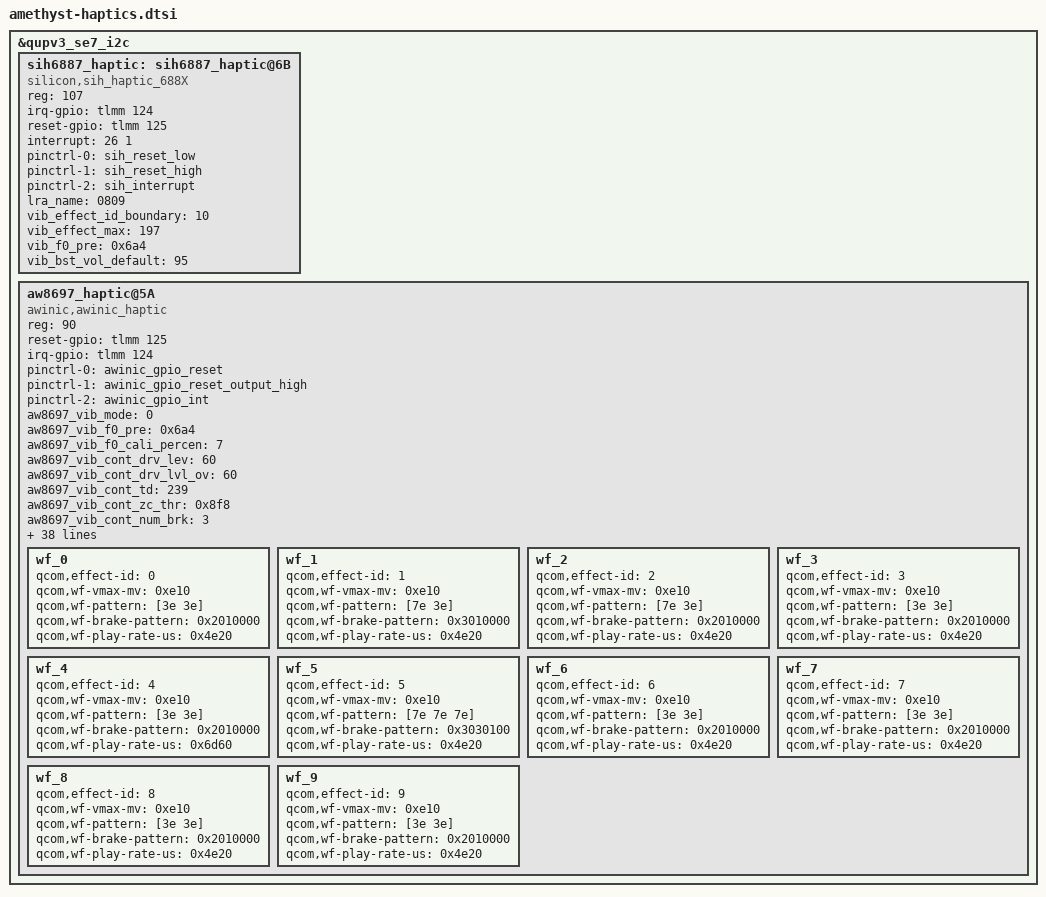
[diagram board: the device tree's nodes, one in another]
/*
 * Amethyst QUPv3 SE7 I2C haptics: Awinic AW8697 (0x5A) and SI-Hub SIH6887
 * (0x6B); the driver that probes picks the fitted part.
 *
 * Reconstructed from stock dtbo.img (dtbo.img:1, fragments 45) with
 * scripts/amethyst-dtbo-to-dts.py; labels and references are the stock
 * ones from __symbols__, __fixups__ and __local_fixups__.
 */

&qupv3_se7_i2c {
	status = "ok";

	sih6887_haptic: sih6887_haptic@6B {
		compatible = "silicon,sih_haptic_688X";
		reg = <107>;
		irq-gpio = <&tlmm 124 0>;
		reset-gpio = <&tlmm 125 0>;
		interrupt = <26 1>;
		pinctrl-names = "sih_reset_reset", "sih_reset_active", "sih_interrupt_active";
		pinctrl-0 = <&sih_reset_low>;
		pinctrl-1 = <&sih_reset_high>;
		pinctrl-2 = <&sih_interrupt>;
		lra_name = "0809";
		vib_effect_id_boundary = <10>;
		vib_effect_max = <197>;
		vib_f0_pre = <0x6a4>;
		vib_bst_vol_default = <95>;
	};

	aw8697_haptic@5A {
		compatible = "awinic,awinic_haptic";
		reg = <90>;
		reset-gpio = <&tlmm 125 0>;
		irq-gpio = <&tlmm 124 0>;
		pinctrl-names = "awinic_reset_reset", "awinic_reset_active",
		                "awinic_interrupt_active";
		pinctrl-0 = <&awinic_gpio_reset>;
		pinctrl-1 = <&awinic_gpio_reset_output_high>;
		pinctrl-2 = <&awinic_gpio_int>;
		aw8697_vib_mode = <0>;
		aw8697_vib_f0_pre = <0x6a4>;
		aw8697_vib_f0_cali_percen = <7>;
		aw8697_vib_cont_drv_lev = <60>;
		aw8697_vib_cont_drv_lvl_ov = <60>;
		aw8697_vib_cont_td = <239>;
		aw8697_vib_cont_zc_thr = <0x8f8>;
		aw8697_vib_cont_num_brk = <3>;
		aw8697_vib_f0_coeff = <260>;
		aw8697_vib_f0_trace_parameter = <9 3 1 31>;
		aw8697_vib_bemf_config = <0 8 3 248>;
		aw8697_vib_sw_brake = <44>;
		aw8697_vib_tset = <26>;
		aw8697_vib_r_spare = <104>;
		aw8697_vib_bstdbg = <48 235 212 0 0 0>;
		aw8697_vib_trig_config = <0 1 0 1 2 0 1 0 1 2 0 1 0 1 2>;
		aw8697_vib_bst_vol_default = <14>;
		aw8697_vib_bst_vol_ram = <14>;
		aw8697_vib_bst_vol_rtp = <14>;
		aw86927_vib_mode = <0>;
		aw86927_vib_f0_pre = <0x6a4>;
		aw86927_vib_f0_cali_percen = <7>;
		aw86927_vib_cont_drv1_lvl = <127>;
		aw86927_vib_cont_drv2_lvl = <54>;
		aw86927_vib_cont_drv1_time = <4>;
		aw86927_vib_cont_drv2_time = <6>;
		aw86927_vib_cont_drv_width = <106>;
		aw86927_vib_cont_wait_num = <6>;
		aw86927_vib_cont_brk_time = <8>;
		aw86927_vib_cont_track_margin = <12>;
		aw86927_vib_brk_bst_md = <0>;
		aw86927_vib_cont_tset = <6>;
		aw86927_vib_cont_bemf_set = <2>;
		aw86927_vib_cont_bst_brk_gain = <5>;
		aw86927_vib_cont_brk_gain = <8>;
		aw86927_vib_d2s_gain = <4>;
		aw86927_vib_trig_config = <0 0 0 1 0 2 0 0 0 0 0 1 0 2 0 0 0 0 0 1 0 2 0 0>;
		aw86927_vib_bst_vol_default = <95>;
		aw86927_vib_bst_vol_ram = <95>;
		aw86927_vib_bst_vol_rtp = <95>;
		vib_effect_id_boundary = <10>;
		vib_effect_max = <197>;
		vib_rtp_time = <20 20 20 20 20 20 20 20 0x4e20 0x3a98 0x3a98 0x4e20 0x61a8
		                0x3a98 0x7530 0x61a8 0x4e20 0x4e20 0x4e20 0x4e20 0x4e20 0x4e20
		                0x4e20 0x4e20 0x4e20 0x4e20 0x4e20 0x4e20 0x4e20 0x4e20 0x4e20
		                0x4e20 0x4e20 0x4e20 0x4e20 0x4e20 0x4e20 0x4e20 0x4e20 0x4e20
		                0x4e20 0x4e20 0x4e20 0x4e20 0x4e20 0x4e20 0x4e20 0x4e20 0x4e20
		                0x4e20 0x4e20 0x4e20 0x4e20 0x4e20 0x4e20 0x4e20 0x4e20 0x4e20
		                0x4e20 0x4e20 0x4e20 0x4e20 0x4e20 0x4e20 0x4e20 0x4e20 0x4e20
		                0x4e20 0x4e20 0x4e20 0x4e20 0x4e20 0x4e20 0x4e20 0x4e20 0x4e20
		                0x4e20 0x4e20 0x4e20 0x4e20 0x4e20 0x4e20 0x4e20 0x4e20 0x4e20
		                0x4e20 0x4e20 0x4e20 0x4e20 0x4e20 0x4e20 0x4e20 0x4e20 0x4e20
		                0x4e20 0x4e20 0x4e20 0x4e20 0x4e20 0x4e20 0x4e20 0x4e20 0x4e20
		                0x4e20 0x4e20 0x4e20 0x4e20 0x4e20 0x4e20 0x4e20 0x4e20 0x4e20
		                0x4e20 0x4e20 0x4e20 0x4e20 0x4e20 0x4e20 0x4e20 0x4e20 0x4e20
		                0x4e20 0x4e20 0x4e20 0x4e20 0x4e20 0x4e20 0x4e20 0x4e20 0x4e20
		                0x4e20 0x4e20 0x4e20 0x4e20 0x4e20 0x4e20 0x4e20 0x4e20 0x4e20
		                0x4e20 0x4e20 0x4e20 0x4e20 0x4e20 0x4e20 0x4e20 0x4e20 0x4e20
		                0x4e20 0x4e20 0x4e20 0x4e20 0x4e20 0x4e20 0x4e20 0x4e20 0x4e20
		                0x4e20 0x4e20 0x4e20 0x4e20 0x4e20 0x4e20 0x4e20 0x4e20 0x4e20
		                0x4e20 0x4e20 0x4e20 0x4e20 0x4e20 0x4e20 0x4e20 0x4e20 0x4e20>;
		status = "ok";

		wf_0 {
			qcom,effect-id = <0>;
			qcom,wf-vmax-mv = <0xe10>;
			qcom,wf-pattern = [3e 3e];
			qcom,wf-brake-pattern = <0x2010000>;
			qcom,wf-play-rate-us = <0x4e20>;
		};

		wf_1 {
			qcom,effect-id = <1>;
			qcom,wf-vmax-mv = <0xe10>;
			qcom,wf-pattern = [7e 3e];
			qcom,wf-brake-pattern = <0x3010000>;
			qcom,wf-play-rate-us = <0x4e20>;
		};

		wf_2 {
			qcom,effect-id = <2>;
			qcom,wf-vmax-mv = <0xe10>;
			qcom,wf-pattern = [7e 3e];
			qcom,wf-brake-pattern = <0x2010000>;
			qcom,wf-play-rate-us = <0x4e20>;
		};

		wf_3 {
			qcom,effect-id = <3>;
			qcom,wf-vmax-mv = <0xe10>;
			qcom,wf-pattern = [3e 3e];
			qcom,wf-brake-pattern = <0x2010000>;
			qcom,wf-play-rate-us = <0x4e20>;
		};

		wf_4 {
			qcom,effect-id = <4>;
			qcom,wf-vmax-mv = <0xe10>;
			qcom,wf-pattern = [3e 3e];
			qcom,wf-brake-pattern = <0x2010000>;
			qcom,wf-play-rate-us = <0x6d60>;
		};

		wf_5 {
			qcom,effect-id = <5>;
			qcom,wf-vmax-mv = <0xe10>;
			qcom,wf-pattern = [7e 7e 7e];
			qcom,wf-brake-pattern = <0x3030100>;
			qcom,wf-play-rate-us = <0x4e20>;
		};

		wf_6 {
			qcom,effect-id = <6>;
			qcom,wf-vmax-mv = <0xe10>;
			qcom,wf-pattern = [3e 3e];
			qcom,wf-brake-pattern = <0x2010000>;
			qcom,wf-play-rate-us = <0x4e20>;
		};

		wf_7 {
			qcom,effect-id = <7>;
			qcom,wf-vmax-mv = <0xe10>;
			qcom,wf-pattern = [3e 3e];
			qcom,wf-brake-pattern = <0x2010000>;
			qcom,wf-play-rate-us = <0x4e20>;
		};

		wf_8 {
			qcom,effect-id = <8>;
			qcom,wf-vmax-mv = <0xe10>;
			qcom,wf-pattern = [3e 3e];
			qcom,wf-brake-pattern = <0x2010000>;
			qcom,wf-play-rate-us = <0x4e20>;
		};

		wf_9 {
			qcom,effect-id = <9>;
			qcom,wf-vmax-mv = <0xe10>;
			qcom,wf-pattern = [3e 3e];
			qcom,wf-brake-pattern = <0x2010000>;
			qcom,wf-play-rate-us = <0x4e20>;
		};
	};
};
